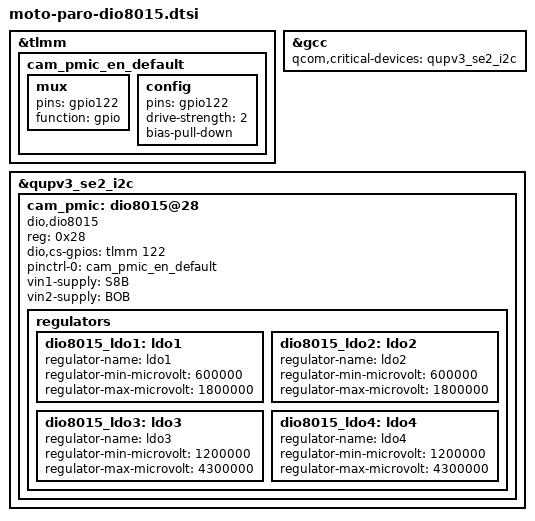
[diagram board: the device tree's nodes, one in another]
&tlmm{
	cam_pmic_en_default: cam_pmic_en_default {
		mux {
		pins = "gpio122";
		function = "gpio";
		};

		config {
		pins = "gpio122";
		drive-strength = <2>;
		bias-pull-down;
		};
	};
};

/*
 * Each QUP device that's a parent to PMIC must be listed as a critical device
 * to GCC.
 */
&gcc {
	qcom,critical-devices = <&qupv3_se2_i2c>;
};

&qupv3_se2_i2c {
	status = "ok";
	cam_pmic: dio8015@28 {
		compatible = "dio,dio8015";
		reg = <0x28>;

		dio,cs-gpios = <&tlmm 122 0>;
		pinctrl-names = "default";
		pinctrl-0 = <&cam_pmic_en_default>;

		vin1-supply = <&S8B>;
		vin2-supply = <&BOB>;

		regulators {
			dio8015_ldo1: ldo1 {
				regulator-name = "ldo1";
				regulator-min-microvolt = <600000>;
				regulator-max-microvolt = <1800000>;
			};

			dio8015_ldo2: ldo2 {
				regulator-name = "ldo2";
				regulator-min-microvolt = <600000>;
				regulator-max-microvolt = <1800000>;
			};

			dio8015_ldo3: ldo3 {
				regulator-name = "ldo3";
				regulator-min-microvolt = <1200000>;
				regulator-max-microvolt = <4300000>;
			};

			dio8015_ldo4: ldo4 {
				regulator-name = "ldo4";
				regulator-min-microvolt = <1200000>;
				regulator-max-microvolt = <4300000>;
			};
		};
	};
};
